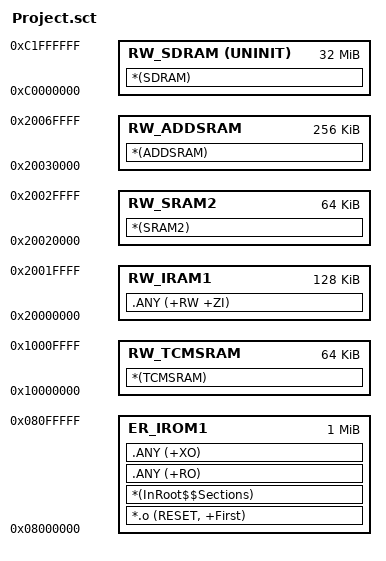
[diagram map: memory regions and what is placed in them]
; *************************************************************
; *** Scatter-Loading Description File generated by uVision ***
; *************************************************************

LR_IROM1 0x08000000 0x100000  {    ; load region size_region 768KB+256KB=1024KB
  ER_IROM1 0x08000000 0x100000  {  ; load address = execution address
   *.o (RESET, +First)
   *(InRoot$$Sections)
   .ANY (+RO)
   .ANY (+XO)
  }
  RW_IRAM1 0x20000000 0x20000  {  ; SRAM0/1 128KB
   .ANY (+RW +ZI)
  }
  RW_SRAM2 0x20020000 0x10000  {  ; SRAM2 64KB
   *(SRAM2)
  }
  RW_ADDSRAM 0x20030000 0x40000  {  ; ADDSRAM 256KB
   *(ADDSRAM)
  }
  RW_TCMSRAM 0x10000000 0x10000  {  ; TCMSRAM 64KB
   *(TCMSRAM)
  }
  
  RW_SDRAM 0xC0000000 UNINIT 0x2000000  {  ; SDRAM 32MB
   *(SDRAM)
  }
;    RW_SDRAM1 0xC0800000 UNINIT 0x1800000  {  ; SDRAM 32MB
;   *(SDRAM_B2)
;  }
}

